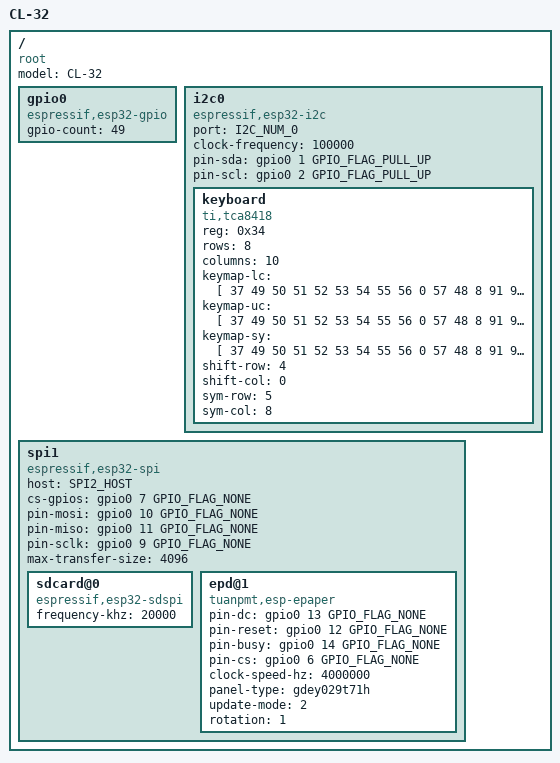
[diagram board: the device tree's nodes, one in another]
/dts-v1/;

#include <tactility/bindings/root.h>
#include <tactility/bindings/esp32_gpio.h>
#include <tactility/bindings/esp32_i2c.h>
#include <tactility/bindings/esp32_spi.h>
#include <tactility/bindings/esp32_sdspi.h>

#include <bindings/tca8418.h>
#include <bindings/esp_epaper.h>

/ {
	compatible = "root";
	model = "CL-32";

	gpio0 {
		compatible = "espressif,esp32-gpio";
		gpio-count = <49>;
	};

	i2c0 {
		compatible = "espressif,esp32-i2c";
		port = <I2C_NUM_0>;
		clock-frequency = <100000>;
		pin-sda = <&gpio0 1 GPIO_FLAG_PULL_UP>;
		pin-scl = <&gpio0 2 GPIO_FLAG_PULL_UP>;

		keyboard {
			compatible = "ti,tca8418";
			reg = <0x34>;
			rows = <8>;
			columns = <10>;
			keymap-lc = [
				37 49 50 51 52 53 54 55 56 0 // % 1 2 3 4 5 6 7 8
				57 48 8 91 93 43 34 39 0 0 // 9 0 BKSP [ ] + " '
				0 113 119 101 114 116 121 117 105 0 //   q w e r t y u i
				111 112 10 40 41 45 59 58 0 0 // o p ENTER ( ) - ; :
				0 97 115 100 102 103 104 106 107 0 //   a s d f g h j k
				108 17 35 123 125 42 44 46 0 0 // l UP # { } * , .
				122 120 99 118 98 32 32 110 109 0 // z x c v b   n m
				20 18 19 60 62 47 92 61 0 0 // LEFT DOWN RIGHT < > / \ =
			];
			keymap-uc = [
				37 49 50 51 52 53 54 55 56 0 // % 1 2 3 4 5 6 7 8
				57 48 8 91 93 43 34 39 0 0 // 9 0 BKSP [ ] + " '
				0 81 87 69 82 84 89 85 73 0 //   Q W E R T Y U I
				79 80 10 40 41 45 59 58 0 0 // O P ENTER ( ) - ; :
				0 65 83 68 70 71 72 74 75 0 //   A S D F G H J K
				76 17 35 123 125 42 44 46 0 0 // L UP # { } * , .
				90 88 67 86 66 32 32 78 77 0 // Z X C V B   N M
				20 18 19 60 62 47 92 61 0 0 // LEFT DOWN RIGHT < > / \ =
			];
			keymap-sy = [
				37 49 50 51 52 53 54 55 56 0 // % 1 2 3 4 5 6 7 8
				57 48 8 91 93 43 34 39 0 0 // 9 0 BKSP [ ] + " '
				0 113 119 101 114 116 121 117 105 0 //   q w e r t y u i
				111 112 10 40 41 45 59 58 0 0 // o p ENTER ( ) - ; :
				0 97 115 100 102 103 104 106 107 0 //   a s d f g h j k
				108 17 35 123 125 42 44 46 0 0 // l UP # { } * , .
				122 120 99 118 98 32 32 110 109 0 // z x c v b   n m
				20 18 19 60 62 47 92 61 0 0 // LEFT DOWN RIGHT < > / \ =
			];
			shift-row = <4>;
			shift-col = <0>;
			sym-row = <5>;
			sym-col = <8>;
		};
	};

	spi1 {
		compatible = "espressif,esp32-spi";
		host = <SPI2_HOST>;
		cs-gpios = <&gpio0 7 GPIO_FLAG_NONE>;
		pin-mosi = <&gpio0 10 GPIO_FLAG_NONE>;
		pin-miso = <&gpio0 11 GPIO_FLAG_NONE>;
		pin-sclk = <&gpio0 9 GPIO_FLAG_NONE>;
		max-transfer-size = <4096>;

		sdcard@0 {
			compatible = "espressif,esp32-sdspi";
			frequency-khz = <20000>;
		};

		epd@1 {
			compatible = "tuanpmt,esp-epaper";
			pin-dc = <&gpio0 13 GPIO_FLAG_NONE>;
			pin-reset = <&gpio0 12 GPIO_FLAG_NONE>;
			pin-busy = <&gpio0 14 GPIO_FLAG_NONE>;
			pin-cs = <&gpio0 6 GPIO_FLAG_NONE>;
			clock-speed-hz = <4000000>;
			panel-type = "gdey029t71h";
			update-mode = <2>;
			rotation = <1>;
		};
	};
};
